# SPC1068 register map
File version: 20180100_70611510
CPU: CM3 r2p1, little endian, MPU, no FPU, 4 interrupt priority bits
Registers are 32-bit, read-write, reset 0x0 unless marked. A register's access mark holds for its fields unless they carry their own. Offsets are from the block's base; [hi:lo] are bit positions; 'fields as' and 'values as' point back to an identical list.

## POWER — Split from GLOBAL
Base 0x4000B000
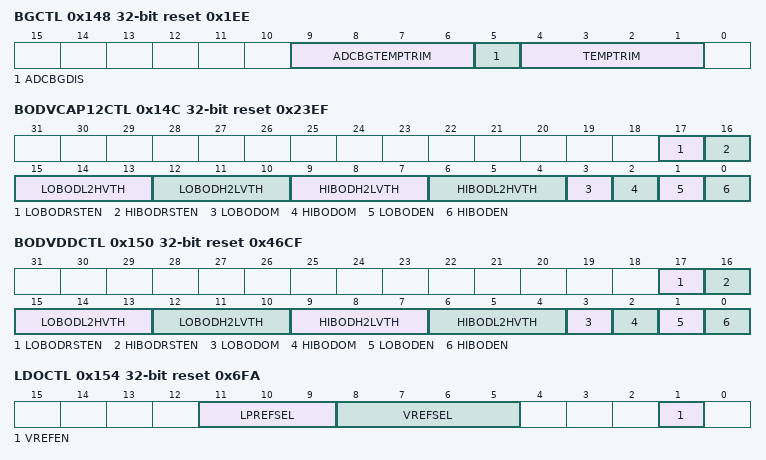
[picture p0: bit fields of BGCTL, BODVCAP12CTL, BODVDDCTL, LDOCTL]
0x148 BGCTL reset 0x1EE — Bandgap Control Register
  [9:6] ADCBGTEMPTRIM — ADCBG temperature coefficient trimming. Optimize this code to minimize temperature dependency
  [5] ADCBGDIS — ADCBG disable
    0=ENABLE_ADC_BANDGAP; 1=DISABLE_ADC_BANDGAP
  [4:1] TEMPTRIM — SYSBG temperature coefficient trimming. Optimize this code to minimize temperature dependency
0x14C BODVCAP12CTL reset 0x23EF — VCAP12 BOD Control Register
  [17] LOBODRSTEN — Enable reset when VCAP12 is too low
    0=DISABLE; 1=ENABLE
  [16] HIBODRSTEN — Enable reset when VCAP12 is too high
    0=DISABLE; 1=ENABLE
  [15:13] LOBODL2HVTH — Select the threshold voltage for VCAP12 too low detection when VCAP12 varies from low to high.
    0=1dot06_V (1.06V); 1=1dot04_V (1.04V); 2=1dot02_V (1.02V); 3=1dot00_V (1.00V); 4=0dot98_V (0.98V); 5=0dot96_V (0.96V); 6=0dot94_V (0.94V); 7=0dot92_V (0.92V)
  [12:10] LOBODH2LVTH — Select the threshold voltage for VCAP12 too low detection when VCAP12 varies from high to low.
    values as LOBODL2HVTH
  [9:7] HIBODH2LVTH — Select the threshold voltage for VCAP12 too high detection when VCAP12 varies from high to low.
    0=1dot50_V (1.50V); 1=1dot48_V (1.48V); 2=1dot45_V (1.45V); 3=1dot43_V (1.43V); 4=1dot41_V (1.41V); 5=1dot39_V (1.39V); 6=1dot37_V (1.37V); 7=1dot35_V (1.35V)
  [6:4] HIBODL2HVTH — Select the threshold voltage for VCAP12 too high detection when VCAP12 varies from low to high.
    values as HIBODH2LVTH
  [3] LOBODOM — VCAP12_TOO_LOW BOD output mask
    0=UNMASK (VCAP12_TOO_LOW follows the BOD result); 1=MASK (VCAP12_TOO_LOW is masked as 0)
  [2] HIBODOM — VCAP12_TOO_HIGH BOD output mask
    0=UNMASK (VCAP12_TOO_HIGH follows the BOD result); 1=MASK (VCAP12_TOO_HIGH is masked as 0)
  [1] LOBODEN — VCAP12_TOO_LOW BOD enable
    0=DISABLE; 1=ENABLE
  [0] HIBODEN — VCAP12_TOO_HIGH BOD enable
    0=DISABLE; 1=ENABLE
0x150 BODVDDCTL reset 0x46CF — VDD BOD Control Register
  [17] LOBODRSTEN — Enable reset when VDD is too low
    0=DISABLE; 1=ENABLE
  [16] HIBODRSTEN — Enable reset when VDD is too high
    0=DISABLE; 1=ENABLE
  [15:13] LOBODL2HVTH — Select the threshold voltage for VDD too low detection when VDD varies from low to high.
    0=3dot11_V (3.11V); 1=3dot02_V (3.02V); 2=2dot93_V (2.93V); 3=2dot85_V (2.85V); 4=2dot78_V (2.78V); 5=2dot71_V (2.71V); 6=2dot64_V (2.64V); 7=2dot58_V (2.58V)
  [12:10] LOBODH2LVTH — Select the threshold voltage for VDD too low detection when VDD varies from high to low.
    values as LOBODL2HVTH
  [9:7] HIBODH2LVTH — Select the threshold voltage for VDD too high detection when VDD varies from high to low.
    0=4dot22_V (4.22V); 1=4dot06_V (4.06V); 2=3dot91_V (3.91V); 3=3dot77_V (3.77V); 4=3dot64_V (3.64V); 5=3dot52_V (3.52V); 6=3dot41_V (3.41V); 7=3dot30_V (3.30V)
  [6:4] HIBODL2HVTH — Select the threshold voltage for VDD too high detection when VDD varies from low to high.
    values as HIBODH2LVTH
  [3] LOBODOM — VDD_TOO_LOW BOD output mask
    0=UNMASK (VDD_TOO_LOW follows the BOD result); 1=MASK (VDD_TOO_LOW is masked as 0)
  [2] HIBODOM — VDD_TOO_HIGH BOD output mask
    0=UNMASK (VDD_TOO_HIGH follows the BOD result); 1=MASK (VDD_TOO_HIGH is masked as 0)
  [1] LOBODEN — VDD_TOO_LOW BOD enable
    0=DISABLE; 1=ENABLE
  [0] HIBODEN — VDD_TOO_HIGH BOD enable
    0=DISABLE; 1=ENABLE
0x154 LDOCTL reset 0x6FA — LDO Control Register
  [11:9] LPREFSEL — Low-power reference voltage select for LDO (Valid when VREFEN=0)
    0=1dot12_V (1.12V); 1=1dot17_V (1.17V); 2=1dot22_V (1.22V); 3=1dot27_V (1.27V); 4=1dot31_V (1.31V); 5=1dot36_V (1.36V); 6=1dot41_V (1.41V); 7=1dot45_V (1.45V)
  [8:5] VREFSEL — Reference voltage select for LDO (Valid when VREFEN=1)
    0=1dot06_V (1.06V); 1=1dot08_V (1.08V); 2=1dot10_V (1.10V); 3=1dot12_V (1.12V); 4=1dot14_V (1.14V); 5=1dot16_V (1.16V); 6=1dot18_V (1.18V); 7=1dot20_V (1.20V); 8=1dot22_V (1.22V); 9=1dot24_V (1.24V); 10=1dot26_V (1.26V); 11=1dot28_V (1.28V); 12=1dot30_V (1.30V); 13=1dot32_V (1.32V); 14=1dot34_V (1.34V); 15=1dot36_V (1.36V)
  [1] VREFEN — Enable high-performance reference for LDO
    0=DISABLE; 1=ENABLE
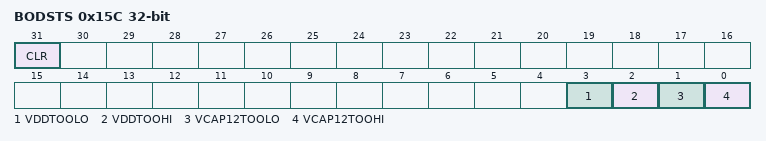
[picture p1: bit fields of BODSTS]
0x15C BODSTS — BOD Status Register
  [31] CLR wo — Clear latched BOD status
    0=NO_EFFECT (Write a 0 has no effect. Always readback 0.); 1=CLEAR (Write a 1 will clear all latched BOD status. This bit is self-cleared to 0.)
  [3] VDDTOOLO ro — Latched VDD_TOO_LOW status
    0=NOT_OCCUR (VDD has never been too low); 1=OCCUR (VDD is used to be too low)
  [2] VDDTOOHI ro — Latched VDD_TOO_HIGH status
    0=NOT_OCCUR (VDD has never been too high); 1=OCCUR (VDD is used to be too high)
  [1] VCAP12TOOLO ro — Latched VCAP12_TOO_LOW status
    0=NOT_OCCUR (VCAP12 has never been too low); 1=OCCUR (VCAP12 is used to be too low)
  [0] VCAP12TOOHI ro — Latched VCAP12_TOO_HIGH status
    0=NOT_OCCUR (VCAP12 has never been too high); 1=OCCUR (VCAP12 is used to be too high)
0x160 BODCTL reset 0x7 — BOD Control Register
  [3:0] VREFSEL — BOD reference voltage select
    0=1dot13_V (1.13V); 1=1dot14_V (1.14V); 2=1dot15_V (1.15V); 3=1dot16_V (1.16V); 4=1dot17_V (1.17V); 5=1dot18_V (1.18V); 6=1dot19_V (1.19V); 7=1dot20_V (1.20V); 8=1dot21_V (1.21V); 9=1dot22_V (1.22V); 10=1dot23_V (1.23V); 11=1dot24_V (1.24V); 12=1dot25_V (1.25V); 13=1dot26_V (1.26V); 14=1dot27_V (1.27V); 15=1dot28_V (1.28V)
